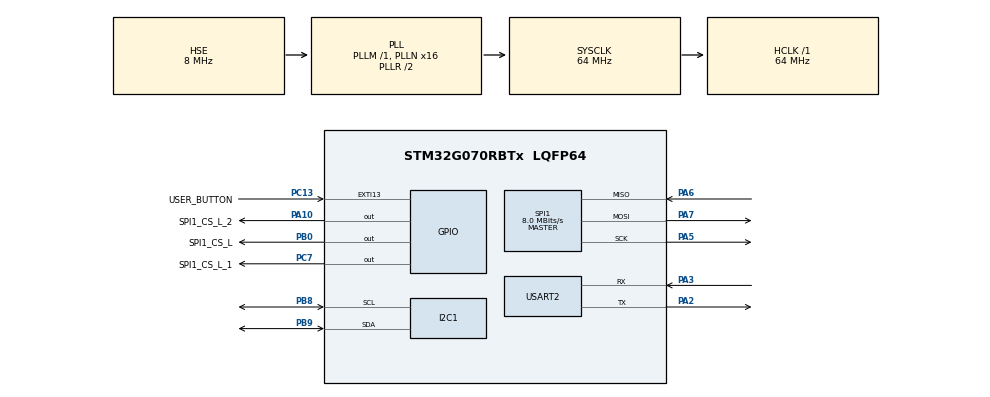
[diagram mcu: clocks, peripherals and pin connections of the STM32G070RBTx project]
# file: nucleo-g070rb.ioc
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I2C1.Timing=0x10707DBC
IWDG.Prescaler=IWDG_PRESCALER_256
Mcu.Family=STM32G0
Mcu.Name=STM32G070RBTx
Mcu.Package=LQFP64
NVIC.EXTI4_15_IRQn=true\:0\:0\:false\:false\:true\:true\:true
NVIC.USART2_IRQn=true\:0\:0\:false\:false\:true\:true\:true
PA10.GPIO_Label=SPI1_CS_L_2
PA10.GPIO_Speed=GPIO_SPEED_FREQ_MEDIUM
PA10.PinState=GPIO_PIN_SET
PA10.Signal=GPIO_Output
PA13.GPIO_Label=TMS
PA13.Mode=Serial_Wire
PA13.Signal=SYS_SWDIO
PA14-BOOT0.GPIO_Label=TCK
PA14-BOOT0.Mode=Serial_Wire
PA14-BOOT0.Signal=SYS_SWCLK
PA2.Mode=Asynchronous
PA2.Signal=USART2_TX
PA3.Mode=Asynchronous
PA3.Signal=USART2_RX
PA5.Mode=Full_Duplex_Master
PA5.Signal=SPI1_SCK
PA6.Mode=Full_Duplex_Master
PA6.Signal=SPI1_MISO
PA7.Mode=Full_Duplex_Master
PA7.Signal=SPI1_MOSI
PB0.GPIO_Label=SPI1_CS_L
PB0.GPIO_Speed=GPIO_SPEED_FREQ_MEDIUM
PB0.PinState=GPIO_PIN_SET
PB0.Signal=GPIO_Output
PB8.Mode=I2C
PB8.Signal=I2C1_SCL
PB9.Mode=I2C
PB9.Signal=I2C1_SDA
PC13.GPIO_Label=USER_BUTTON
PC13.Signal=GPXTI13
PC14-OSC32_IN\ (PC14).Signal=RCC_OSC32_IN
PC15-OSC32_OUT\ (PC15).Signal=RCC_OSC32_OUT
PC7.GPIO_Label=SPI1_CS_L_1
PC7.GPIO_Speed=GPIO_SPEED_FREQ_MEDIUM
PC7.PinState=GPIO_PIN_SET
PC7.Signal=GPIO_Output
PF0-OSC_IN\ (PF0).GPIO_Label=MCO
PF0-OSC_IN\ (PF0).Mode=HSE-External-Clock-Source
PF0-OSC_IN\ (PF0).Signal=RCC_OSC_IN
ProjectManager.HeapSize=0x200
ProjectManager.StackSize=0x400
ProjectManager.TargetToolchain=Makefile
RCC.ADCFreq_Value=64000000
RCC.AHBFreq_Value=64000000
RCC.CortexFreq_Value=64000000
RCC.EXTERNAL_CLOCK_VALUE=12288000
RCC.HCLKFreq_Value=64000000
RCC.HSE_VALUE=8000000
RCC.HSI_VALUE=16000000
RCC.LSE_VALUE=32768
RCC.PLLN=16
RCC.PLLSourceVirtual=RCC_PLLSOURCE_HSE
RCC.RTCClockSelection=RCC_RTCCLKSOURCE_HSE_DIV32
RCC.SYSCLKFreq_VALUE=64000000
RCC.SYSCLKSource=RCC_SYSCLKSOURCE_PLLCLK
RCC.VCOOutputFreq_Value=128000000
RTC.AsynchPrediv=125
RTC.SynchPrediv=2000
SPI1.BaudRatePrescaler=SPI_BAUDRATEPRESCALER_8
SPI1.CalculateBaudRate=8.0 MBits/s
SPI1.DataSize=SPI_DATASIZE_8BIT
SPI1.Direction=SPI_DIRECTION_2LINES
SPI1.Mode=SPI_MODE_MASTER
SPI1.VirtualType=VM_MASTER
USART2.VirtualMode-Asynchronous=VM_ASYNC
VP_IWDG_VS_IWDG.Mode=IWDG_Activate
VP_RTC_VS_RTC_Activate.Mode=RTC_Enabled
VP_SYS_VS_DBSignals.Mode=DisableDeadBatterySignals
board=NUCLEO-G070RB

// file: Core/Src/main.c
/* USER CODE BEGIN Header */
/**
  ******************************************************************************
  * @file           : main.c
  * @brief          : Main program body
  ******************************************************************************
  * @attention
  *
  * <h2><center>&copy; Copyright (c) 2021 STMicroelectronics.
  * All rights reserved.</center></h2>
  *
  * This software component is licensed by ST under BSD 3-Clause license,
  * the "License"; You may not use this file except in compliance with the
  * License. You may obtain a copy of the License at:
  *                        opensource.org/licenses/BSD-3-Clause
  *
  ******************************************************************************
  */
/* USER CODE END Header */
#include "main.h"

/* USER CODE BEGIN Includes */

#include "startup.h"

/* USER CODE END Includes */

I2C_HandleTypeDef hi2c1;

IWDG_HandleTypeDef hiwdg;

RTC_HandleTypeDef hrtc;

SPI_HandleTypeDef hspi1;

UART_HandleTypeDef huart2;

void SystemClock_Config(void);
static void MX_GPIO_Init(void);
static void MX_I2C1_Init(void);
static void MX_IWDG_Init(void);
static void MX_RTC_Init(void);
static void MX_SPI1_Init(void);
static void MX_USART2_UART_Init(void);

int main(void)
{

  /* MCU Configuration--------------------------------------------------------*/

  /* Reset of all peripherals, Initializes the Flash interface and the Systick. */
  HAL_Init();

  /* Configure the system clock */
  SystemClock_Config();

  /* USER CODE BEGIN SysInit */

  note_reset_cause();

  /* USER CODE END SysInit */

  /* Initialize all configured peripherals */
  MX_GPIO_Init();
  MX_I2C1_Init();
  MX_IWDG_Init();
  MX_RTC_Init();
  MX_SPI1_Init();
  MX_USART2_UART_Init();
  /* USER CODE BEGIN 2 */
  user_main();

  /* USER CODE END 2 */

  /* Infinite loop */
  while (1)
  {

  }
}

void SystemClock_Config(void)
{
  RCC_OscInitTypeDef RCC_OscInitStruct = {0};
  RCC_ClkInitTypeDef RCC_ClkInitStruct = {0};
  RCC_PeriphCLKInitTypeDef PeriphClkInit = {0};

  /** Configure the main internal regulator output voltage
  */
  HAL_PWREx_ControlVoltageScaling(PWR_REGULATOR_VOLTAGE_SCALE1);
  /** Initializes the RCC Oscillators according to the specified parameters
  * in the RCC_OscInitTypeDef structure.
  */
  RCC_OscInitStruct.OscillatorType = RCC_OSCILLATORTYPE_LSI|RCC_OSCILLATORTYPE_HSE;
  RCC_OscInitStruct.HSEState = RCC_HSE_BYPASS;
  RCC_OscInitStruct.LSIState = RCC_LSI_ON;
  RCC_OscInitStruct.PLL.PLLState = RCC_PLL_ON;
  RCC_OscInitStruct.PLL.PLLSource = RCC_PLLSOURCE_HSE;
  RCC_OscInitStruct.PLL.PLLM = RCC_PLLM_DIV1;
  RCC_OscInitStruct.PLL.PLLN = 16;
  RCC_OscInitStruct.PLL.PLLP = RCC_PLLP_DIV2;
  RCC_OscInitStruct.PLL.PLLR = RCC_PLLR_DIV2;
  if (HAL_RCC_OscConfig(&RCC_OscInitStruct) != HAL_OK)
  {
    Error_Handler();
  }
  /** Initializes the CPU, AHB and APB buses clocks
  */
  RCC_ClkInitStruct.ClockType = RCC_CLOCKTYPE_HCLK|RCC_CLOCKTYPE_SYSCLK
                              |RCC_CLOCKTYPE_PCLK1;
  RCC_ClkInitStruct.SYSCLKSource = RCC_SYSCLKSOURCE_PLLCLK;
  RCC_ClkInitStruct.AHBCLKDivider = RCC_SYSCLK_DIV1;
  RCC_ClkInitStruct.APB1CLKDivider = RCC_HCLK_DIV1;

  if (HAL_RCC_ClockConfig(&RCC_ClkInitStruct, FLASH_LATENCY_2) != HAL_OK)
  {
    Error_Handler();
  }
  /** Initializes the peripherals clocks
  */
  PeriphClkInit.PeriphClockSelection = RCC_PERIPHCLK_RTC|RCC_PERIPHCLK_USART2
                              |RCC_PERIPHCLK_I2C1;
  PeriphClkInit.Usart2ClockSelection = RCC_USART2CLKSOURCE_PCLK1;
  PeriphClkInit.I2c1ClockSelection = RCC_I2C1CLKSOURCE_PCLK1;
  PeriphClkInit.RTCClockSelection = RCC_RTCCLKSOURCE_HSE_DIV32;

  if (HAL_RCCEx_PeriphCLKConfig(&PeriphClkInit) != HAL_OK)
  {
    Error_Handler();
  }
}

static void MX_I2C1_Init(void)
{

  hi2c1.Instance = I2C1;
  hi2c1.Init.Timing = 0x10707DBC;
  hi2c1.Init.OwnAddress1 = 0;
  hi2c1.Init.AddressingMode = I2C_ADDRESSINGMODE_7BIT;
  hi2c1.Init.DualAddressMode = I2C_DUALADDRESS_DISABLE;
  hi2c1.Init.OwnAddress2 = 0;
  hi2c1.Init.OwnAddress2Masks = I2C_OA2_NOMASK;
  hi2c1.Init.GeneralCallMode = I2C_GENERALCALL_DISABLE;
  hi2c1.Init.NoStretchMode = I2C_NOSTRETCH_DISABLE;
  if (HAL_I2C_Init(&hi2c1) != HAL_OK)
  {
    Error_Handler();
  }
  /** Configure Analogue filter
  */
  if (HAL_I2CEx_ConfigAnalogFilter(&hi2c1, I2C_ANALOGFILTER_ENABLE) != HAL_OK)
  {
    Error_Handler();
  }
  /** Configure Digital filter
  */
  if (HAL_I2CEx_ConfigDigitalFilter(&hi2c1, 0) != HAL_OK)
  {
    Error_Handler();
  }

}

static void MX_IWDG_Init(void)
{

  hiwdg.Instance = IWDG;
  hiwdg.Init.Prescaler = IWDG_PRESCALER_256;
  hiwdg.Init.Window = 4095;
  hiwdg.Init.Reload = 4095;
  if (HAL_IWDG_Init(&hiwdg) != HAL_OK)
  {
    Error_Handler();
  }

}

static void MX_RTC_Init(void)
{

  /** Initialize RTC Only
  */
  hrtc.Instance = RTC;
  hrtc.Init.HourFormat = RTC_HOURFORMAT_24;
  hrtc.Init.AsynchPrediv = 125;
  hrtc.Init.SynchPrediv = 2000;
  hrtc.Init.OutPut = RTC_OUTPUT_DISABLE;
  hrtc.Init.OutPutRemap = RTC_OUTPUT_REMAP_NONE;
  hrtc.Init.OutPutPolarity = RTC_OUTPUT_POLARITY_HIGH;
  hrtc.Init.OutPutType = RTC_OUTPUT_TYPE_OPENDRAIN;
  hrtc.Init.OutPutPullUp = RTC_OUTPUT_PULLUP_NONE;
  if (HAL_RTC_Init(&hrtc) != HAL_OK)
  {
    Error_Handler();
  }

}

static void MX_SPI1_Init(void)
{

  /* SPI1 parameter configuration*/
  hspi1.Instance = SPI1;
  hspi1.Init.Mode = SPI_MODE_MASTER;
  hspi1.Init.Direction = SPI_DIRECTION_2LINES;
  hspi1.Init.DataSize = SPI_DATASIZE_8BIT;
  hspi1.Init.CLKPolarity = SPI_POLARITY_LOW;
  hspi1.Init.CLKPhase = SPI_PHASE_1EDGE;
  hspi1.Init.NSS = SPI_NSS_SOFT;
  hspi1.Init.BaudRatePrescaler = SPI_BAUDRATEPRESCALER_8;
  hspi1.Init.FirstBit = SPI_FIRSTBIT_MSB;
  hspi1.Init.TIMode = SPI_TIMODE_DISABLE;
  hspi1.Init.CRCCalculation = SPI_CRCCALCULATION_DISABLE;
  hspi1.Init.CRCPolynomial = 7;
  hspi1.Init.CRCLength = SPI_CRC_LENGTH_DATASIZE;
  hspi1.Init.NSSPMode = SPI_NSS_PULSE_ENABLE;
  if (HAL_SPI_Init(&hspi1) != HAL_OK)
  {
    Error_Handler();
  }

}

static void MX_USART2_UART_Init(void)
{

  huart2.Instance = USART2;
  huart2.Init.BaudRate = 115200;
  huart2.Init.WordLength = UART_WORDLENGTH_8B;
  huart2.Init.StopBits = UART_STOPBITS_1;
  huart2.Init.Parity = UART_PARITY_NONE;
  huart2.Init.Mode = UART_MODE_TX_RX;
  huart2.Init.HwFlowCtl = UART_HWCONTROL_NONE;
  huart2.Init.OverSampling = UART_OVERSAMPLING_16;
  huart2.Init.OneBitSampling = UART_ONE_BIT_SAMPLE_DISABLE;
  huart2.Init.ClockPrescaler = UART_PRESCALER_DIV1;
  huart2.AdvancedInit.AdvFeatureInit = UART_ADVFEATURE_NO_INIT;
  if (HAL_UART_Init(&huart2) != HAL_OK)
  {
    Error_Handler();
  }
  if (HAL_UARTEx_SetTxFifoThreshold(&huart2, UART_TXFIFO_THRESHOLD_1_8) != HAL_OK)
  {
    Error_Handler();
  }
  if (HAL_UARTEx_SetRxFifoThreshold(&huart2, UART_RXFIFO_THRESHOLD_1_8) != HAL_OK)
  {
    Error_Handler();
  }
  if (HAL_UARTEx_DisableFifoMode(&huart2) != HAL_OK)
  {
    Error_Handler();
  }

}

static void MX_GPIO_Init(void)
{
  GPIO_InitTypeDef GPIO_InitStruct = {0};

  /* GPIO Ports Clock Enable */
  __HAL_RCC_GPIOC_CLK_ENABLE();
  __HAL_RCC_GPIOF_CLK_ENABLE();
  __HAL_RCC_GPIOA_CLK_ENABLE();
  __HAL_RCC_GPIOB_CLK_ENABLE();

  /*Configure GPIO pin Output Level */
  HAL_GPIO_WritePin(SPI1_CS_L_GPIO_Port, SPI1_CS_L_Pin, GPIO_PIN_SET);

  /*Configure GPIO pin Output Level */
  HAL_GPIO_WritePin(SPI1_CS_L_1_GPIO_Port, SPI1_CS_L_1_Pin, GPIO_PIN_SET);

  /*Configure GPIO pin Output Level */
  HAL_GPIO_WritePin(SPI1_CS_L_2_GPIO_Port, SPI1_CS_L_2_Pin, GPIO_PIN_SET);

  /*Configure GPIO pin : USER_BUTTON_Pin */
  GPIO_InitStruct.Pin = USER_BUTTON_Pin;
  GPIO_InitStruct.Mode = GPIO_MODE_IT_RISING;
  GPIO_InitStruct.Pull = GPIO_NOPULL;
  HAL_GPIO_Init(USER_BUTTON_GPIO_Port, &GPIO_InitStruct);

  /*Configure GPIO pin : SPI1_CS_L_Pin */
  GPIO_InitStruct.Pin = SPI1_CS_L_Pin;
  GPIO_InitStruct.Mode = GPIO_MODE_OUTPUT_PP;
  GPIO_InitStruct.Pull = GPIO_NOPULL;
  GPIO_InitStruct.Speed = GPIO_SPEED_FREQ_MEDIUM;
  HAL_GPIO_Init(SPI1_CS_L_GPIO_Port, &GPIO_InitStruct);

  /*Configure GPIO pin : SPI1_CS_L_1_Pin */
  GPIO_InitStruct.Pin = SPI1_CS_L_1_Pin;
  GPIO_InitStruct.Mode = GPIO_MODE_OUTPUT_PP;
  GPIO_InitStruct.Pull = GPIO_NOPULL;
  GPIO_InitStruct.Speed = GPIO_SPEED_FREQ_MEDIUM;
  HAL_GPIO_Init(SPI1_CS_L_1_GPIO_Port, &GPIO_InitStruct);

  /*Configure GPIO pin : SPI1_CS_L_2_Pin */
  GPIO_InitStruct.Pin = SPI1_CS_L_2_Pin;
  GPIO_InitStruct.Mode = GPIO_MODE_OUTPUT_PP;
  GPIO_InitStruct.Pull = GPIO_NOPULL;
  GPIO_InitStruct.Speed = GPIO_SPEED_FREQ_MEDIUM;
  HAL_GPIO_Init(SPI1_CS_L_2_GPIO_Port, &GPIO_InitStruct);

  /* EXTI interrupt init*/
  HAL_NVIC_SetPriority(EXTI4_15_IRQn, 0, 0);
  HAL_NVIC_EnableIRQ(EXTI4_15_IRQn);

}

void Error_Handler(void)
{
  __disable_irq();
  while (1)
  {
  }
}

/************************ (C) COPYRIGHT STMicroelectronics *****END OF FILE****/
